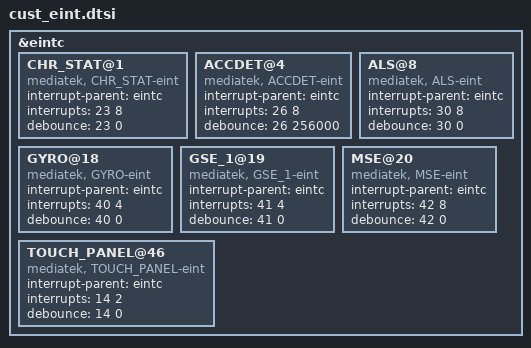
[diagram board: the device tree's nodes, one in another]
/*
 * Generated by MTK SP DrvGen Version 03.13.6 for MT8163. Copyright MediaTek Inc. (C) 2013.
 * Sun Feb 05 14:26:23 2017
 * Do Not Modify the File.
 */

/*************************
 * EINT DTSI File
*************************/

&eintc {
	CHR_STAT@1 {
		compatible = "mediatek, CHR_STAT-eint";
		interrupt-parent = <&eintc>;
		interrupts = <23 8>;
		debounce = <23 0>;
	};

	ACCDET@4 {
		compatible = "mediatek, ACCDET-eint";
		interrupt-parent = <&eintc>;
		interrupts = <26 8>;
		debounce = <26 256000>;
	};

	ALS@8 {
		compatible = "mediatek, ALS-eint";
		interrupt-parent = <&eintc>;
		interrupts = <30 8>;
		debounce = <30 0>;
	};

	GYRO@18 {
		compatible = "mediatek, GYRO-eint";
		interrupt-parent = <&eintc>;
		interrupts = <40 4>;
		debounce = <40 0>;
	};

	GSE_1@19 {
		compatible = "mediatek, GSE_1-eint";
		interrupt-parent = <&eintc>;
		interrupts = <41 4>;
		debounce = <41 0>;
	};

	MSE@20 {
		compatible = "mediatek, MSE-eint";
		interrupt-parent = <&eintc>;
		interrupts = <42 8>;
		debounce = <42 0>;
	};

	TOUCH_PANEL@46 {
		compatible = "mediatek, TOUCH_PANEL-eint";
		interrupt-parent = <&eintc>;
		interrupts = <14 2>;
		debounce = <14 0>;
	};

};
